# RTS5921 register map
Vendor: Realtek Semiconductor Corp.; Series: RTS5921 Series; File version: 0.01
CPU: ARMV8MBL r0p0, little endian, MPU, no FPU, VTOR, 3 interrupt priority bits
Registers are 32-bit, read-write, reset 0x0 unless marked. A register's access mark holds for its fields unless they carry their own. Offsets are from the block's base; [hi:lo] are bit positions; {n}, {i} and the like mark numbered series; 'fields as' and 'values as' point back to an identical list.

## USB_DEVICE — USB OTG Device Controller
Base 0x40040800
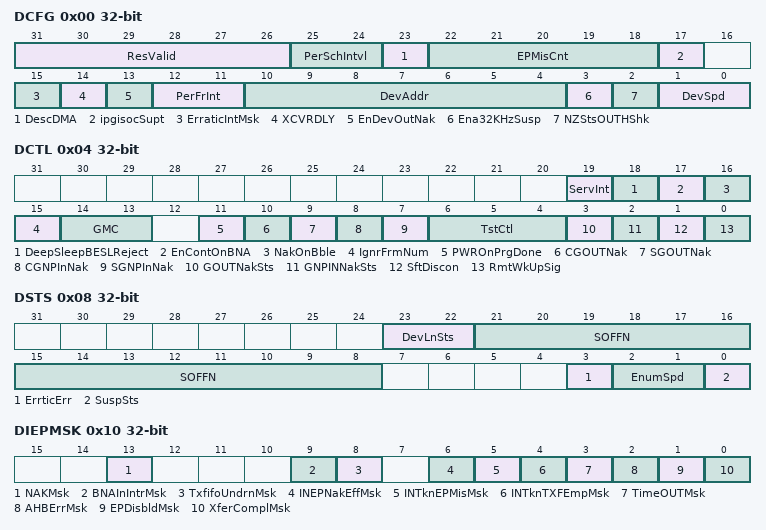
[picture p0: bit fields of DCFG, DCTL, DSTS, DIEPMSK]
0x00 DCFG — Device Configuration Register
  [31:26] ResValid — Resume Validation Period. Effective only when Ena32KHzSusp is set. Value after reset: 0x2
  [25:24] PerSchIntvl — Periodic Scheduling Interval.
    0=MF25 (25% of (micro)Frame); 1=MF50 (50% of (micro)Frame); 2=MF75 (75% of (micro)Frame)
  [23] DescDMA — Enable Scatter/Gather DMA in device mode. One-time programmable after reset. Value after reset: 0x0
    0=DISABLED (Disable Scatter/Gather DMA); 1=ENABLED (Enable Scatter/Gather DMA)
  [22:18] EPMisCnt — IN Endpoint Mismatch Count (Shared FIFO only). Value after reset: 0x8
  [17] ipgisocSupt — Worst-Case Inter-Packet Gap ISOC OUT Support. Value after reset: 0x1
    0=DISABLED (Support disabled); 1=ENABLED (Support enabled)
  [15] ErraticIntMsk — Erratic Error Interrupt Mask. Value after reset: 0x0
    0=NOMASK (Interrupt generated); 1=MASK (Interrupt masked)
  [14] XCVRDLY — XCVR Delay between xcvr_sel and txvalid during device chirp. Value after reset: 0x0
    0=DISABLE (No delay); 1=ENABLE (Enable delay)
  [13] EnDevOutNak — Enable Device OUT NAK after Bulk OUT transfer complete (only for Descriptor DMA mode). Value after reset: 0x0
    0=DISABLED (Not set NAK); 1=ENABLED (Set NAK)
  [12:11] PerFrInt — Periodic Frame Interval End-Of-Periodic Frame Interrupt time. 0x0: 80% 0x1: 85% 0x2: 90% 0x3: 95% Value after reset: 0x0
    0=EOPF80 (80% of (micro)Frame); 1=EOPF85 (85% of (micro)Frame); 2=EOPF90 (90% of (micro)Frame); 3=EOPF95 (95% of (micro)Frame)
  [10:4] DevAddr — Device address. Must be set after SetAddress command. Value after reset: 0x0
  [3] Ena32KHzSusp — Enable 32KHz Suspend mode, only valid for FS PHY. Value after reset: 0x0
    0=DISABLED (Not in 32KHz suspend); 1=ENABLED (32KHz suspend enabled)
  [2] NZStsOUTHShk — Non-Zero-Length Status OUT Handshake on receiving status OUT. 0: Send PKT to app, handshake follows endpoint config 1: STALL on NZL status OUT, do not send to app Value after reset: 0x0
    0=SENDOUT (Send received OUT packet to application (zero or nonzero) and handshake as per endpoint); 1=SENDSTALL (Send STALL on nonzero-length status OUT)
  [1:0] DevSpd — Device Speed for enumeration. 0x0: High speed (USB 2.0, 30/60MHz) 0x1: Full speed (USB 2.0, 30/60MHz) 0x2: Low speed (USB 1.1, 6MHz) 0x3: Full speed (USB 1.1, 48MHz) Value after reset: 0x0
    0=USBHS20 (High speed USB 2.0 PHY clock is 30 MHz or 60 MHz); 1=USBFS20 (Full speed USB 2.0 PHY clock is 30 MHz or 60 MHz); 2=USBLS116 (Low speed USB 1.1 transceiver clock is 6 MHz); 3=USBFS1148 (Full speed USB 1.1 transceiver clock is 48 MHz)
0x04 DCTL — Device Control Register
  [19] ServInt — Enable Service Interval scheduling for ISOC IN EP
    0=DISABLED; 1=ENABLED
  [18] DeepSleepBESLReject — Enable Deep Sleep BESL Reject
    0=DISABLED; 1=ENABLED
  [17] EnContOnBNA — Continue on BNA (DMA mode)
    0=DISABLED; 1=ENABLED
  [16] NakOnBble — NAK on Babble Error
    0=DISABLED; 1=ENABLED
  [15] IgnrFrmNum — Ignore Frame Number / Enable PTI Mode
    0=DISABLED; 1=ENABLED
  [14:13] GMC — Global Multi Packet Count
    0=INVALID; 1=ONE (1 packet); 2=TWO (2 packets); 3=THREE (3 packets)
  [11] PWROnPrgDone — Power-On Programming Done
    0=NOTDONE; 1=DONE
  [10] CGOUTNak wo — Clear Global OUT NAK
    0=DISABLED; 1=ENABLED
  [9] SGOUTNak wo — Set Global OUT NAK
    0=DISABLED; 1=ENABLED
  [8] CGNPInNak wo — Clear Global Non-Periodic IN NAK
    0=DISABLE (Disabled); 1=ENABLE (Enabled)
  [7] SGNPInNak wo — Set Global Non-Periodic IN NAK
    0=DISABLE (Disabled); 1=ENABLE (Enabled)
  [6:4] TstCtl — Test Control
    0=DISABLED (Test mode disabled); 1=TESTJ; 2=TESTK; 3=TESTSN (Test SE0 NAK); 4=TESTPM (Test Packet); 5=TESTFE (Test Force Enable)
  [3] GOUTNakSts ro — Global OUT NAK Status
    0=INACTIVE; 1=ACTIVE
  [2] GNPINNakSts ro — Global Non-Periodic IN NAK Status
    0=INACTIVE; 1=ACTIVE
  [1] SftDiscon — Soft Disconnect
    0=NODISCONNECT (Connected); 1=DISCONNECT (Disconnected)
  [0] RmtWkUpSig — Remote Wakeup Signaling
    0=DISABLED; 1=ENABLED
0x08 DSTS — Device Status Register
  [23:22] DevLnSts ro — Current logic level of USB D+ and D- lines
  [21:8] SOFFN ro — Current frame or microframe number
  [3] ErrticErr ro — Erratic error detected
    0=INACTIVE (No erratic error); 1=ACTIVE (Erratic error)
  [2:1] EnumSpd ro — Enumerated USB speed
    0=HS3060 (High speed (30/60 MHz)); 1=FS3060 (Full speed (30/60 MHz)); 2=LS6 (Low speed (6 MHz)); 3=FS48 (Full speed (48 MHz))
  [0] SuspSts ro — Device is in suspend state
    0=INACTIVE (Not suspended); 1=ACTIVE (Suspended)
0x10 DIEPMSK — Device IN Endpoint Common Interrupt Mask Register
  [13] NAKMsk — NAK interrupt mask
    0=MASK (Mask NAK Interrupt); 1=NOMASK (No Mask NAK Interrupt)
  [9] BNAInIntrMsk — BNA interrupt mask
    0=MASK (Mask BNA Interrupt); 1=NOMASK (No Mask BNA Interrupt)
  [8] TxfifoUndrnMsk — FIFO underrun interrupt mask
    0=MASK (Mask FIFO Underrun Interrupt); 1=NOMASK (No Mask FIFO Underrun Interrupt)
  [6] INEPNakEffMsk — IN EP NAK effective interrupt mask
    0=MASK (Mask IN EP NAK Effective Interrupt); 1=NOMASK (No Mask IN EP NAK Effective Interrupt)
  [5] INTknEPMisMsk — IN token EP mismatch interrupt mask
    0=MASK (Mask IN Token EP Mismatch Interrupt); 1=NOMASK (No Mask IN Token EP Mismatch Interrupt)
  [4] INTknTXFEmpMsk — IN token TxFIFO empty interrupt mask
    0=MASK (Mask IN Token Received When TxFIFO Empty Interrupt); 1=NOMASK (No Mask IN Token Received When TxFIFO Empty Interrupt)
  [3] TimeOUTMsk — Timeout condition interrupt mask
    0=MASK (Mask Timeout Condition Interrupt); 1=NOMASK (No Mask Timeout Condition Interrupt)
  [2] AHBErrMsk — AHB error interrupt mask
    0=MASK (Mask AHB Error Interrupt); 1=NOMASK (No Mask AHB Error Interrupt)
  [1] EPDisbldMsk — Endpoint disabled interrupt mask
    0=MASK (Mask Endpoint Disabled Interrupt); 1=NOMASK (No Mask Endpoint Disabled Interrupt)
  [0] XferComplMsk — Transfer completed interrupt mask
    0=MASK (Mask Transfer Completed Interrupt); 1=NOMASK (No Mask Transfer Completed Interrupt)
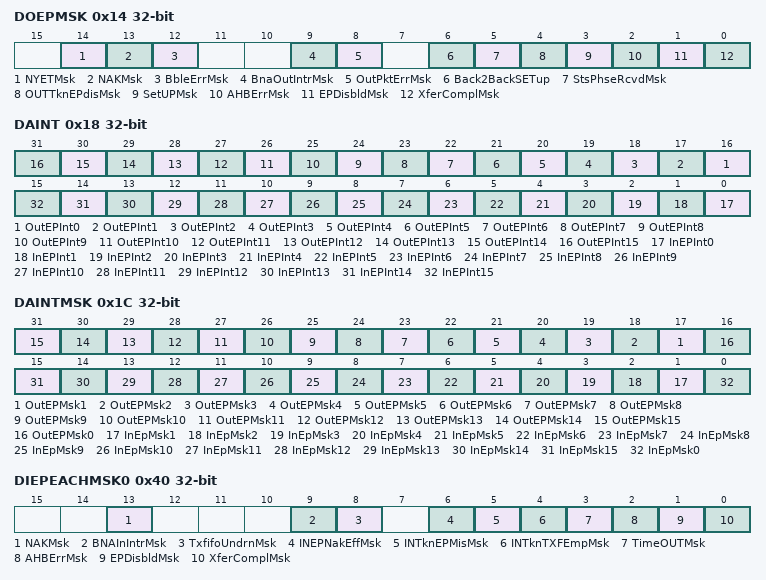
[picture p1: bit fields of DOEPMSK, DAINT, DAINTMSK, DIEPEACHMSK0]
0x14 DOEPMSK — Device OUT Endpoint Common Interrupt Mask Register
  [14] NYETMsk — NYET interrupt mask
    0=MASK (Mask NYET Interrupt); 1=NOMASK (No NYET Interrupt Mask)
  [13] NAKMsk — NAK interrupt mask
    0=MASK (Mask NAK Interrupt); 1=NOMASK (No NAK Interrupt Mask)
  [12] BbleErrMsk — Babble error interrupt mask
    0=MASK (Mask Babble Error Interrupt); 1=NOMASK (No Babble Error Interrupt Mask)
  [9] BnaOutIntrMsk — BNA interrupt mask
    0=MASK (Mask BNA Interrupt); 1=NOMASK (No BNA Interrupt Mask)
  [8] OutPktErrMsk — OUT packet error interrupt mask
    0=MASK (Mask OUT Packet Error Interrupt); 1=NOMASK (No OUT Packet Error Interrupt Mask)
  [6] Back2BackSETup — Back-to-back SETUP packets mask
    0=MASK (Mask Interrupt); 1=NOMASK (No Interrupt Mask)
  [5] StsPhseRcvdMsk — Status phase received mask
    0=MASK (Mask Status Phase Received Interrupt); 1=NOMASK (No Status Phase Received Interrupt Mask)
  [4] OUTTknEPdisMsk — OUT token received when EP disabled mask
    0=MASK (Mask OUT Token Received when Endpoint Disabled Interrupt); 1=NOMASK (No OUT Token Received when Endpoint Disabled Interrupt Mask)
  [3] SetUPMsk — SETUP phase done interrupt mask
    0=MASK (Mask SETUP Phase Done Interrupt); 1=NOMASK (No SETUP Phase Done Interrupt Mask)
  [2] AHBErrMsk — AHB error interrupt mask
    0=MASK (Mask AHB Error Interrupt); 1=NOMASK (No AHB Error Interrupt Mask)
  [1] EPDisbldMsk — Endpoint disabled interrupt mask
    0=MASK (Mask Endpoint Disabled Interrupt); 1=NOMASK (No Endpoint Disabled Interrupt Mask)
  [0] XferComplMsk — Transfer completed interrupt mask
    0=MASK (Mask Transfer Completed Interrupt); 1=NOMASK (No Transfer Completed Interrupt Mask)
0x18 DAINT — Device All Endpoints Interrupt Register
  [all] fields
    0=INACTIVE (No interrupt); 1=ACTIVE (Interrupt active)
  [n+16] OutEPInt{n} ro (n=0..15) — OUT EP{n} interrupt
  [n] InEPInt{n} ro (n=0..15) — IN EP{n} interrupt
0x1C DAINTMSK — Device All Endpoints Interrupt Mask Register
  [n+16] OutEPMsk{n} (n=1..15) — OUT EP{n} interrupt mask
    0=MASK (Mask OUT Endpoint Interrupt); 1=NOMASK (No Interrupt mask)
  [16] OutEPMsk0 — OUT EP0 interrupt mask
    0=MASK (Mask OUT Endpoint 0 Interrupt); 1=NOMASK (No Interrupt mask)
  [n] InEpMsk{n} (n=1..15) — IN EP{n} interrupt mask
    0=MASK (Mask IN Endpoint Interrupt); 1=NOMASK (No Interrupt mask)
  [0] InEpMsk0 — IN EP0 interrupt mask
    0=MASK (Mask IN Endpoint 0 Interrupt); 1=NOMASK (No Interrupt mask)
0x28 DVBUSDIS — Device VBUS Discharge Time Register
0x2C DVBUSPULSE — Device VBUS Pulsing Time Register
0x30 DTHRCTL — Device Threshold Control Register
0x34 DIEPEMPMSK — Device IN Endpoint FIFO Empty Interrupt Mask Register
0x38 DEACHINT — Device Each Endpoints Interrupt Register
0x3C DEACHINTMSK — Device Each Endpoints Interrupt Mask Register
0x40 DIEPEACHMSK0 — Device Each IN Endpoint 0 Interrupt Register
  [13] NAKMsk — NAK interrupt mask
    0=MASK (Mask NAK interrupt); 1=NOMASK (No NAK interrupt mask)
  [9] BNAInIntrMsk — BNA interrupt mask
    0=MASK (Mask BNA interrupt); 1=NOMASK (No BNA interrupt mask)
  [8] TxfifoUndrnMsk — Fifo underrun mask
    0=MASK (Mask Fifo underrun); 1=NOMASK (No Fifo underrun mask)
  [6] INEPNakEffMsk — IN endpoint NAK effective mask
    0=MASK (Mask IN NAK effective); 1=NOMASK (No IN NAK effective mask)
  [5] INTknEPMisMsk — IN token EP mismatch mask
    0=MASK (Mask IN token EP mismatch); 1=NOMASK (No IN token EP mismatch mask)
  [4] INTknTXFEmpMsk — IN token TxFIFO empty mask
    0=MASK (Mask IN token TxFIFO empty); 1=NOMASK (No IN token TxFIFO empty mask)
  [3] TimeOUTMsk — Timeout condition mask
    0=MASK (Mask timeout condition); 1=NOMASK (No timeout mask)
  [2] AHBErrMsk — AHB error mask
    0=MASK (Mask AHB error); 1=NOMASK (No AHB error mask)
  [1] EPDisbldMsk — EP disabled interrupt mask
    0=MASK (Mask EP disabled interrupt); 1=NOMASK (No EP disabled mask)
  [0] XferComplMsk — Transfer completed interrupt mask
    0=MASK (Mask transfer completed); 1=NOMASK (No transfer completed mask)
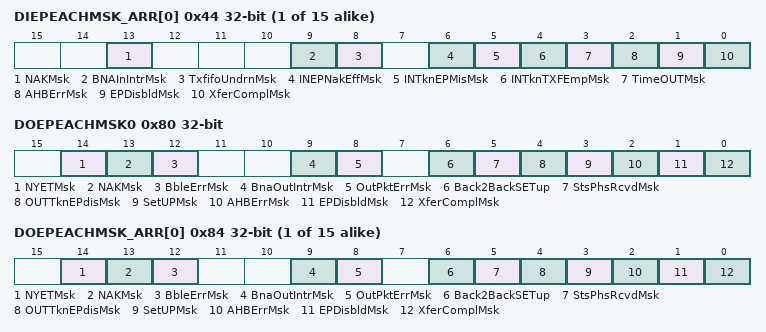
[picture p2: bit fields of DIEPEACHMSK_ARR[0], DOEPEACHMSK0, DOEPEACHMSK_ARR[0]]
{0x44+4i} DIEPEACHMSK_ARR[{i}] (i=0..14) — Device Each IN Endpoint Interrupt Registers
  [13] NAKMsk — NAK interrupt mask
    values as DOEPMSK.NAKMsk
  [9] BNAInIntrMsk — BNA interrupt mask
    values as DOEPMSK.BnaOutIntrMsk
  [8] TxfifoUndrnMsk — Fifo underrun mask
    0=MASK (Mask Fifo Underrun Interrupt); 1=NOMASK (No Fifo Underrun Interrupt Mask)
  [6] INEPNakEffMsk — IN endpoint NAK effective mask
    0=MASK (Mask IN Endpoint NAK Effective); 1=NOMASK (No IN Endpoint NAK Effective Mask)
  [5] INTknEPMisMsk — IN token EP mismatch mask
    0=MASK (Mask IN Token received with EP Mismatch Interrupt); 1=NOMASK (No Mask IN Token received with EP Mismatch Interrupt)
  [4] INTknTXFEmpMsk — IN token TxFIFO empty mask
    0=MASK (Mask IN Token Received When TxFIFO Empty Interrupt); 1=NOMASK (No IN Token Received When TxFIFO Empty Interrupt)
  [3] TimeOUTMsk — Timeout condition mask (Non-isochronous endpoints)
    0=MASK (Mask Timeout Condition Interrupt); 1=NOMASK (No Timeout Condition Interrupt Mask)
  [2] AHBErrMsk — AHB error mask
    0=MASK (Mask AHB Error); 1=NOMASK (No AHB Error Mask)
  [1] EPDisbldMsk — Endpoint disabled interrupt mask
    values as DOEPMSK.EPDisbldMsk
  [0] XferComplMsk — Transfer completed interrupt mask
    values as DOEPMSK.XferComplMsk
0x80 DOEPEACHMSK0 — Device Each OUT Endpoint 0 Interrupt Registers
  [14] NYETMsk — NYET interrupt mask
    values as DOEPMSK.NYETMsk
  [13] NAKMsk — NAK interrupt mask
    values as DOEPMSK.NAKMsk
  [12] BbleErrMsk — Babble error mask
    values as DOEPMSK.BbleErrMsk
  [9] BnaOutIntrMsk — BNA interrupt mask
    values as DOEPMSK.BnaOutIntrMsk
  [8] OutPktErrMsk — OUT packet error mask
    0=MASK (Mask OUT Packet Error); 1=NOMASK (No OUT Packet Error Mask)
  [6] Back2BackSETup — Back-to-Back SETUP packets mask
    0=MASK (Mask Back-to-Back SETUP Packets); 1=NOMASK (No Back-to-Back SETUP Mask)
  [5] StsPhsRcvdMsk — Status phase received mask
    0=MASK (Mask Status Phase Received); 1=NOMASK (No Status Phase Received Mask)
  [4] OUTTknEPdisMsk — OUT token EP disabled mask
    0=MASK (Mask OUT Token Received when Endpoint Disabled); 1=NOMASK (No OUT Token Received when Endpoint Disabled Mask)
  [3] SetUPMsk — SETUP phase done mask
    0=MASK (Mask SETUP Phase Done); 1=NOMASK (No SETUP Phase Done Mask)
  [2] AHBErrMsk — AHB error mask
    0=MASK (Mask AHB Error); 1=NOMASK (No AHB Error Mask)
  [1] EPDisbldMsk — Endpoint disabled interrupt mask
    values as DOEPMSK.EPDisbldMsk
  [0] XferComplMsk — Transfer completed interrupt mask
    values as DOEPMSK.XferComplMsk
{0x84+4i} DOEPEACHMSK_ARR[{i}] (i=0..14) — Device Each OUT Endpoint Interrupt Registers
  [14] NYETMsk — NYET interrupt mask
    0=MASK (Mask NYET interrupt); 1=NOMASK (No NYET interrupt mask)
  [13] NAKMsk — NAK response received mask
    0=MASK (Mask NAK response received); 1=NOMASK (No NAK response received mask)
  [12] BbleErrMsk — Babble error mask
    0=MASK (Mask Babble Error interrupt); 1=NOMASK (No Babble Error interrupt mask)
  [9] BnaOutIntrMsk — BNA interrupt mask
    values as DIEPEACHMSK0.BNAInIntrMsk
  [8] OutPktErrMsk — OUT packet error mask
    0=MASK (Mask OUT packet error interrupt); 1=NOMASK (No OUT packet error interrupt mask)
  [6] Back2BackSETup — Back-to-Back SETUP packets received mask
    0=MASK (Mask Back-to-Back SETUP packets received); 1=NOMASK (No Back-to-Back SETUP received mask)
  [5] StsPhsRcvdMsk — Status phase received mask
    0=MASK (Mask Status Phase Received); 1=NOMASK (No Status Phase Received mask)
  [4] OUTTknEPdisMsk — OUT token received when endpoint disabled mask
    0=MASK (Mask OUT Token received when EP disabled); 1=NOMASK (No OUT Token Received when EP disabled mask)
  [3] SetUPMsk — SETUP phase done mask
    0=MASK (Mask SETUP Phase Done interrupt); 1=NOMASK (No SETUP Phase Done interrupt mask)
  [2] AHBErrMsk — AHB error mask
    0=MASK (Mask AHB error); 1=NOMASK (No AHB error mask)
  [1] EPDisbldMsk — Endpoint disabled interrupt mask
    0=MASK (Mask Endpoint Disabled interrupt); 1=NOMASK (No Endpoint Disabled interrupt mask)
  [0] XferComplMsk — Transfer completed mask
    0=MASK (Transfer Completed Mask); 1=NOMASK (No Transfer Completed mask)
